# STM32L4x2 register map
File version: 2.3
CPU: CM4 r0p1, little endian, MPU, FPU, 4 interrupt priority bits
Registers are 32-bit, read-write, reset 0x0 unless marked. A register's access mark holds for its fields unless they carry their own. Offsets are from the block's base; [hi:lo] are bit positions; {n}, {i} and the like mark numbered series.

## FLASH
Base 0x40022000
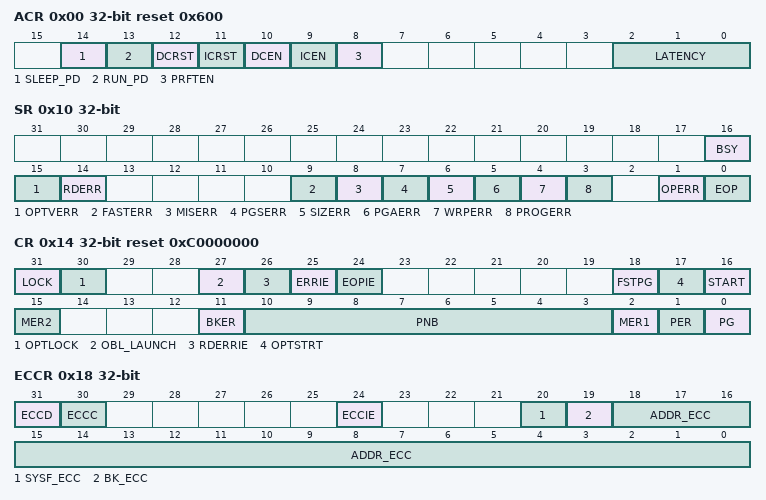
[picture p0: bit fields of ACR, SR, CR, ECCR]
0x00 ACR reset 0x600 — Access control register
  [14] SLEEP_PD — Flash Power-down mode during Low-power sleep mode
  [13] RUN_PD — Flash Power-down mode during Low-power run mode
  [12] DCRST — Data cache reset
  [11] ICRST — Instruction cache reset
  [10] DCEN — Data cache enable
  [9] ICEN — Instruction cache enable
  [8] PRFTEN — Prefetch enable
  [2:0] LATENCY
0x04 PDKEYR wo — Power down key register
  [31:0] PDKEYR — RUN_PD in FLASH_ACR key
0x08 KEYR wo — Flash key register
0x0C OPTKEYR wo — Option byte key register
  [31:0] OPTKEYR — Option byte key
0x10 SR access per field — Status register
  [16] BSY ro — Busy
  [15] OPTVERR rw — Option validity error
  [14] RDERR rw — PCROP read error
  [9] FASTERR rw — Fast programming error
  [8] MISERR rw — Fast programming data miss error
  [7] PGSERR rw — Programming sequence error
  [6] SIZERR rw — Size error
  [5] PGAERR rw — Programming alignment error
  [4] WRPERR rw — Write protected error
  [3] PROGERR rw — Programming error
  [1] OPERR rw — Operation error
  [0] EOP rw — End of operation
0x14 CR reset 0xC0000000 — Flash control register
  [31] LOCK — FLASH_CR Lock
  [30] OPTLOCK — Options Lock
  [27] OBL_LAUNCH — Force the option byte loading
  [26] RDERRIE — PCROP read error interrupt enable
  [25] ERRIE — Error interrupt enable
  [24] EOPIE — End of operation interrupt enable
  [18] FSTPG — Fast programming
  [17] OPTSTRT — Options modification start
  [16] START
  [15] MER2 — Bank 2 Mass erase
  [11] BKER — Bank erase
  [10:3] PNB — Page number
  [2] MER1 — Bank 1 Mass erase
  [1] PER — Page erase
  [0] PG — Programming
0x18 ECCR access per field — Flash ECC register
  [31] ECCD rw — ECC detection
  [30] ECCC rw — ECC correction
  [24] ECCIE rw — ECC correction interrupt enable
  [20] SYSF_ECC ro — System Flash ECC fail
  [19] BK_ECC ro — ECC fail bank
  [18:0] ADDR_ECC ro — ECC fail address
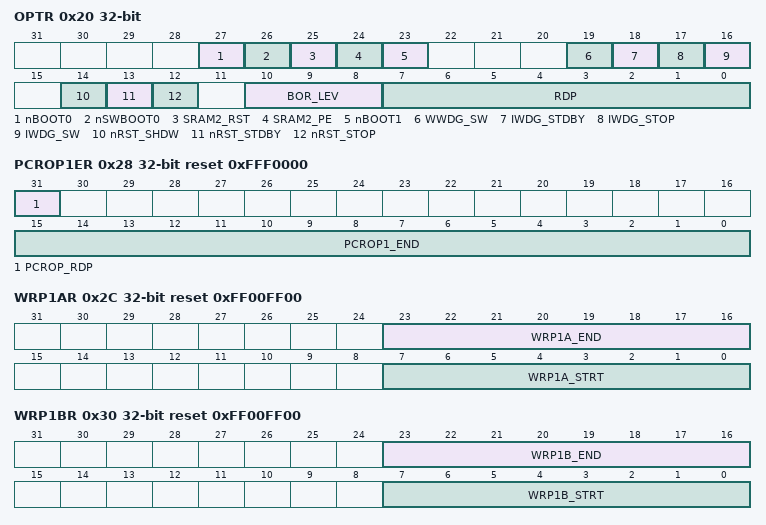
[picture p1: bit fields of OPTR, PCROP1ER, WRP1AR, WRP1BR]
0x20 OPTR — Flash option register
  [27] nBOOT0 — nBOOT0 option bit
  [26] nSWBOOT0 — Software BOOT0
  [25] SRAM2_RST — SRAM2 Erase when system reset
  [24] SRAM2_PE — SRAM2 parity check enable
  [23] nBOOT1 — Boot configuration
  [19] WWDG_SW — Window watchdog selection
  [18] IWDG_STDBY — Independent watchdog counter freeze in Standby mode
  [17] IWDG_STOP — Independent watchdog counter freeze in Stop mode
  [16] IWDG_SW — Independent watchdog selection
  [14] nRST_SHDW
  [13] nRST_STDBY
  [12] nRST_STOP
  [10:8] BOR_LEV — BOR reset Level
  [7:0] RDP — Read protection level
0x24 PCROP1SR reset 0xFFFF0000 — Flash Bank 1 PCROP Start address register
  [15:0] PCROP1_STRT — Bank 1 PCROP area start offset
0x28 PCROP1ER reset 0xFFF0000 — Flash Bank 1 PCROP End address register
  [31] PCROP_RDP — PCROP area preserved when RDP level decreased
  [15:0] PCROP1_END — Bank 1 PCROP area end offset
0x2C WRP1AR reset 0xFF00FF00 — Flash Bank 1 WRP area A address register
  [23:16] WRP1A_END — WRP first area A end offset
  [7:0] WRP1A_STRT — WRP first area A start offset
0x30 WRP1BR reset 0xFF00FF00 — Flash Bank 1 WRP area B address register
  [23:16] WRP1B_END — Bank 1 WRP second area B end offset
  [7:0] WRP1B_STRT — Bank 1 WRP second area B start offset

## PWR — Power control
Base 0x40007000
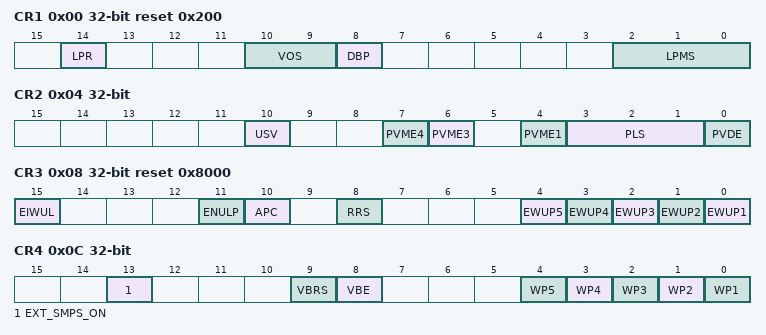
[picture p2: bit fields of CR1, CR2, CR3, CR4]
0x00 CR1 reset 0x200 — Power control register 1
  [14] LPR — Low-power run
  [10:9] VOS — Voltage scaling range selection
  [8] DBP — Disable backup domain write protection
  [2:0] LPMS — Low-power mode selection
0x04 CR2 — Power control register 2
  [10] USV — VDDUSB USB supply valid
  [7] PVME4 — Peripheral voltage monitoring 4 enable: VDDA vs. 2.2V
  [6] PVME3 — Peripheral voltage monitoring 3 enable: VDDA vs. 1.62V
  [4] PVME1 — Peripheral voltage monitoring 1 enable: VDDUSB vs. 1.2V
  [3:1] PLS — Power voltage detector level selection
  [0] PVDE — Power voltage detector enable
0x08 CR3 reset 0x8000 — Power control register 3
  [15] EIWUL — Enable internal wakeup line
  [11] ENULP — Enable ULP sampling of BOR and PVD
  [10] APC — Apply pull-up and pull-down configuration
  [8] RRS — SRAM2 retention in Standby mode
  [n-1] EWUP{n} (n=1..5) — Enable Wakeup pin WKUP{n}
0x0C CR4 — Power control register 4
  [13] EXT_SMPS_ON — External SMPS On
  [9] VBRS — VBAT battery charging resistor selection
  [8] VBE — VBAT battery charging enable
  [n-1] WP{n} (n=1..5) — Wakeup pin WKUP{n} polarity
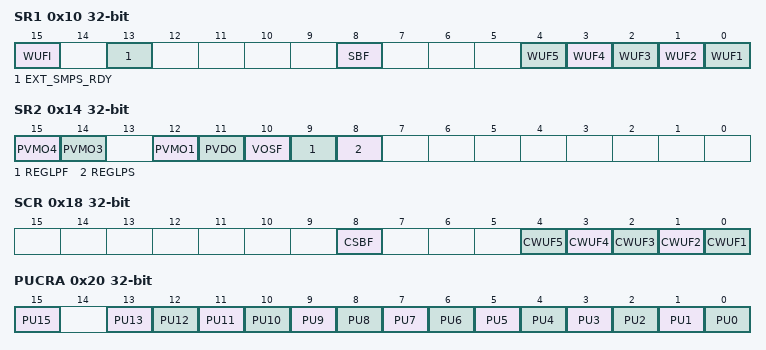
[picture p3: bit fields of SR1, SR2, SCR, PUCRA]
0x10 SR1 ro — Power status register 1
  [15] WUFI — Wakeup flag internal
  [13] EXT_SMPS_RDY — External SMPS Ready
  [8] SBF — Standby flag
  [n-1] WUF{n} (n=1..5) — Wakeup flag {n}
0x14 SR2 ro — Power status register 2
  [15] PVMO4 — Peripheral voltage monitoring output: VDDA vs. 2.2 V
  [14] PVMO3 — Peripheral voltage monitoring output: VDDA vs. 1.62 V
  [12] PVMO1 — Peripheral voltage monitoring output: VDDUSB vs. 1.2 V
  [11] PVDO — Power voltage detector output
  [10] VOSF — Voltage scaling flag
  [9] REGLPF — Low-power regulator flag
  [8] REGLPS — Low-power regulator started
0x18 SCR wo — Power status clear register
  [8] CSBF — Clear standby flag
  [n-1] CWUF{n} (n=1..5) — Clear wakeup flag {n}
0x20 PUCRA — Power Port A pull-up control register
  [15] PU15 — Port A pull-up bit y (y=0..15)
  [n] PU{n} (n=0..13) — Port A pull-up bit y (y=0..15)
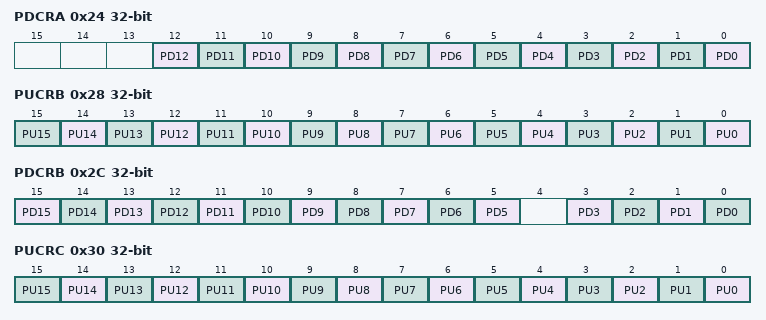
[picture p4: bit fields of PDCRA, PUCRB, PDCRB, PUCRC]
0x24 PDCRA — Power Port A pull-down control register
  [n] PD{n} (n=0..12) — Port A pull-down bit y (y=0..15)
0x28 PUCRB — Power Port B pull-up control register
  [n] PU{n} (n=0..15) — Port B pull-up bit y (y=0..15)
0x2C PDCRB — Power Port B pull-down control register
  [n] PD{n} (n=5..15) — Port B pull-down bit y (y=0..15)
  [n] PD{n} (n=0..3) — Port B pull-down bit y (y=0..15)
0x30 PUCRC — Power Port C pull-up control register
  [n] PU{n} (n=0..15) — Port C pull-up bit y (y=0..15)
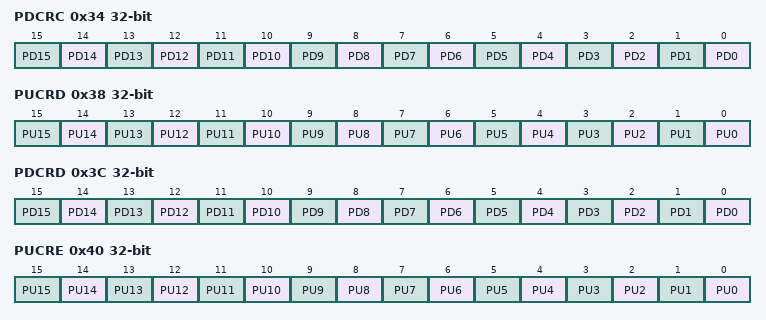
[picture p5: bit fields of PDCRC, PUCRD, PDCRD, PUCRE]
0x34 PDCRC — Power Port C pull-down control register
  [n] PD{n} (n=0..15) — Port C pull-down bit y (y=0..15)
0x38 PUCRD — Power Port D pull-up control register
  [n] PU{n} (n=0..15) — Port D pull-up bit y (y=0..15)
0x3C PDCRD — Power Port D pull-down control register
  [n] PD{n} (n=0..15) — Port D pull-down bit y (y=0..15)
0x40 PUCRE — Power Port E pull-up control register
  [n] PU{n} (n=0..15) — Port E pull-up bit y (y=0..15)
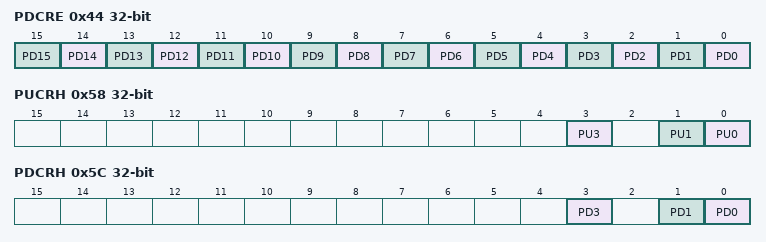
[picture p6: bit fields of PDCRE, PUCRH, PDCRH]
0x44 PDCRE — Power Port E pull-down control register
  [n] PD{n} (n=0..15) — Port E pull-down bit y (y=0..15)
0x58 PUCRH — Power Port H pull-up control register
  [3] PU3 — Port H pull-up bit y (y=0..1)
  [1] PU1 — Port H pull-up bit y (y=0..1)
  [0] PU0 — Port H pull-up bit y (y=0..1)
0x5C PDCRH — Power Port H pull-down control register
  [3] PD3 — Port H pull-down bit y (y=0..1)
  [1] PD1 — Port H pull-down bit y (y=0..1)
  [0] PD0 — Port H pull-down bit y (y=0..1)
